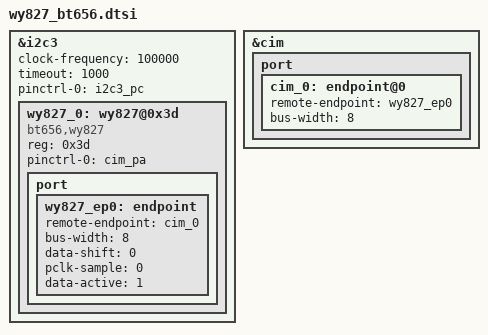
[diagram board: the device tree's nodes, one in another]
&i2c3 {
	status = "okay";
	clock-frequency = <100000>;
	timeout = <1000>;
	pinctrl-names = "default";
	pinctrl-0 = <&i2c3_pc>;

	wy827_0:wy827@0x3d {
		status = "ok";
		compatible = "bt656,wy827";
		reg = <0x3d>;
		pinctrl-names = "default";
		pinctrl-0 = <&cim_pa>;

		port {
			wy827_ep0:endpoint {
				remote-endpoint = <&cim_0>;
				bus-width = <8>;	/* Used data lines */
				data-shift = <0>;	/* Lines 9:0 are used */

				/* If hsync-active/vsync-active are missing,
				   embedded BT.656 sync is used */
				pclk-sample = <0>;	/* Falling */
				data-active = <1>;	/* Active high */
			};
		};
	};
};

&cim {
	status = "okay";
	port {
		cim_0: endpoint@0 {
			remote-endpoint = <&wy827_ep0>;
			bus-width = <8>;
		};
	};
};




